AUTOSAR XML (schema 4-2-1)
package /COM/VECTOR/CFG/WORKFLOW/SYSDESC/SYNC
  system SYSTEM
    system mapping MAPPINGS
      data-mappings:
        data-element=COMPOSITIONTYPE.PpChargingIn.DeCharging, system-signal=sig_SolarPanelSwitch
        data-element=COMPOSITIONTYPE.PpSpeedLimitOut.DeSpeedLimit, system-signal=sig_SpeedLimit
        data-element=COMPOSITIONTYPE.PpSunlightIn.DeSunlight, system-signal=sig_SunlightPresence
        data-element=COMPOSITIONTYPE.PpLockIn.DeLock, system-signal=sig_Locking
        data-element=COMPOSITIONTYPE.PpBatteryStatusOut.DeBatteryStatus, system-signal=sig_BatteryStatus
        data-element=COMPOSITIONTYPE.PpIgnitionIn.DeIgnition, system-signal=sig_Ignition
    root-software-compositions:
      root sw composition prototype COMPOSITIONTYPE: flat-map=FLATMAP, software-composition=COMPOSITIONTYPE
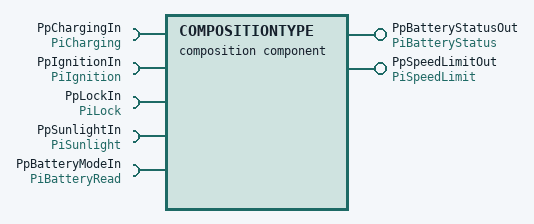
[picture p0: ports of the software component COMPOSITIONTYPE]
  composition sw component type COMPOSITIONTYPE
    provide port PpBatteryStatusOut: nonqueued-sender-com-spec=data-element=DeBatteryStatus, provided-interface=PiBatteryStatus
    provide port PpSpeedLimitOut: nonqueued-sender-com-spec=data-element=DeSpeedLimit, provided-interface=PiSpeedLimit
    5 x require port:
      PpChargingIn: nonqueued-receiver-com-spec{data-element=DeCharging, filter=data-filter-type=ALWAYS}, required-interface=PiCharging
      PpIgnitionIn: nonqueued-receiver-com-spec{data-element=DeIgnition, filter=data-filter-type=ALWAYS}, required-interface=PiIgnition
      PpLockIn: nonqueued-receiver-com-spec{data-element=DeLock, filter=data-filter-type=ALWAYS}, required-interface=PiLock
      PpSunlightIn: nonqueued-receiver-com-spec{data-element=DeSunlight, filter=data-filter-type=ALWAYS}, required-interface=PiSunlight
      PpBatteryModeIn: required-interface=PiBatteryRead
    16 x component:
      Dem: type=Dem
      Det: type=Det
      EcuM: type=EcuM
      NvM: type=NvM
      ComM: type=ComM
      BswM: type=BswM
      Dcm: type=Dcm
      CtSaBattery: type=CtSaBatteryManagement
      CpIoHwAb: type=CtIoHwAb
      CpSaSunlightPresence: type=CtSaSunlightPresence
      CpSaSpeedLimit: type=CtSaSpeedLimit
      CpSaSolarPanelControl: type=CtSaSolarPanelControl
      CpSaLockControl: type=CtSaLockControl
      CpSaEngineControl: type=CtSaEngineControl
      CpApSEVMIController: type=CtApSEVMIController
      CtSaBatteryModeManager: type=CtSaBatteryModeManager
    connect BswM.Switch_ESH_ModeSwitch -> BswM.Notification_ESH_ModeNotification
    connect CpSaEngineControl.PpIgnition -> CpApSEVMIController.PpIgnition
    connect CpSaLockControl.PpLock -> CpApSEVMIController.PpLock
    connect CpSaSolarPanelControl.PpCharging -> CpApSEVMIController.PpCharging
    connect CpSaSunlightPresence.PpSunlight -> CpApSEVMIController.PpSunlight
    connect CpApSEVMIController.PpSpeedLimit -> CpSaSpeedLimit.PpSpeedLimit
    connect CpApSEVMIController.PpBatteryStatus -> CtSaBattery.PpBatteryStatus
    connect CpIoHwAb.PpSpeed -> CpApSEVMIController.PpSpeed
    delegate CpSaSpeedLimit.PpSpeedLimitOut <-> outer port PpSpeedLimitOut
    delegate CtSaBattery.PpBatteryStatusOut <-> outer port PpBatteryStatusOut
    delegate CpSaSunlightPresence.PpSunlightIn <-> outer port PpSunlightIn
    delegate CpSaLockControl.PpLockIn <-> outer port PpLockIn
    delegate CpSaEngineControl.PpIgnitionIn <-> outer port PpIgnitionIn
    delegate CpSaSolarPanelControl.PpChargingIn <-> outer port PpChargingIn
    connect ComM.UR_USR_CHNL_CAN00 -> CpApSEVMIController.PpComMUserRequestCtApSEVMIController
    connect ComM.UM_USR_CHNL_CAN00 -> CpApSEVMIController.PpComMCurrentModeSEVMIController
    connect CtSaBatteryModeManager.PpBatteryMode -> CpApSEVMIController.PpBatteryMode
    delegate CtSaBatteryModeManager.PpBatteryModeIn <-> outer port PpBatteryModeIn
    connect CpApSEVMIController.NvMNotifyJobFinished_SnNvMPimDoorLock -> NvM.NvM_RpNotifyJobEnd_CpApSEVMIControllerSnNvMPimDoorLock
    connect NvM.PS_CpApSEVMIControllerSnNvMPimDoorLock -> CpApSEVMIController.PpNvMLockingCtApMySwc
  end to end protection set E2EPROTECTIONSET
  port interface mapping set PORTINTERFACEMAPPINGSET
